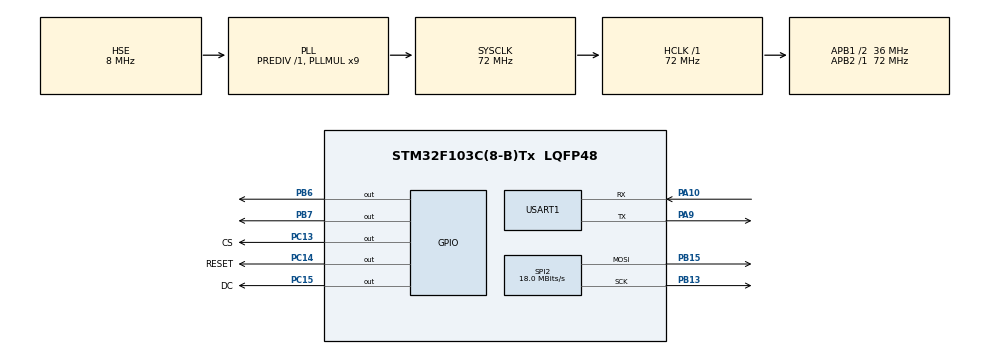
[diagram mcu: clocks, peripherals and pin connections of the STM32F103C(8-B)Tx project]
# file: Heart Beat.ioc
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Mcu.Family=STM32F1
Mcu.Name=STM32F103C(8-B)Tx
Mcu.Package=LQFP48
NVIC.PriorityGroup=NVIC_PRIORITYGROUP_4
NVIC.SPI2_IRQn=true\:2\:0\:true\:false\:true\:true\:true\:true
NVIC.USART1_IRQn=true\:1\:0\:true\:false\:true\:true\:true\:true
PA10.Mode=Asynchronous
PA10.Signal=USART1_RX
PA9.Mode=Asynchronous
PA9.Signal=USART1_TX
PB13.Mode=TX_Only_Simplex_Unidirect_Master
PB13.Signal=SPI2_SCK
PB15.Mode=TX_Only_Simplex_Unidirect_Master
PB15.Signal=SPI2_MOSI
PB6.GPIO_Speed=GPIO_SPEED_FREQ_HIGH
PB6.PinState=GPIO_PIN_SET
PB6.Signal=GPIO_Output
PB7.GPIO_Speed=GPIO_SPEED_FREQ_HIGH
PB7.PinState=GPIO_PIN_SET
PB7.Signal=GPIO_Output
PC13-TAMPER-RTC.GPIO_Label=CS
PC13-TAMPER-RTC.Signal=GPIO_Output
PC14-OSC32_IN.GPIO_Label=RESET
PC14-OSC32_IN.Signal=GPIO_Output
PC15-OSC32_OUT.GPIO_Label=DC
PC15-OSC32_OUT.Signal=GPIO_Output
PD0-OSC_IN.Mode=HSE-External-Oscillator
PD0-OSC_IN.Signal=RCC_OSC_IN
PD1-OSC_OUT.Mode=HSE-External-Oscillator
PD1-OSC_OUT.Signal=RCC_OSC_OUT
ProjectManager.HeapSize=0x200
ProjectManager.StackSize=0x400
ProjectManager.TargetToolchain=STM32CubeIDE
RCC.AHBFreq_Value=72000000
RCC.APB1CLKDivider=RCC_HCLK_DIV2
RCC.APB1Freq_Value=36000000
RCC.APB1TimFreq_Value=72000000
RCC.APB2Freq_Value=72000000
RCC.APB2TimFreq_Value=72000000
RCC.HCLKFreq_Value=72000000
RCC.PLLMUL=RCC_PLL_MUL9
RCC.PLLSourceVirtual=RCC_PLLSOURCE_HSE
RCC.SYSCLKFreq_VALUE=72000000
RCC.SYSCLKSource=RCC_SYSCLKSOURCE_PLLCLK
RCC.USBFreq_Value=72000000
SPI2.CalculateBaudRate=18.0 MBits/s
SPI2.Direction=SPI_DIRECTION_2LINES
SPI2.Mode=SPI_MODE_MASTER
SPI2.VirtualType=VM_MASTER
USART1.VirtualMode=VM_ASYNC
VP_SYS_VS_ND.Mode=No_Debug
board=custom

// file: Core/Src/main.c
/**
  ******************************************************************************
  * @file           : main.c
  * @brief          : Main program body (Final Working Version)
  ******************************************************************************
  */
#include "main.h"

/* USER CODE BEGIN Includes */
#include <ST7735.h>
#include "user_main.h"

/* USER CODE END Includes */

SPI_HandleTypeDef hspi2;

UART_HandleTypeDef huart1;

void SystemClock_Config(void);
static void MX_GPIO_Init(void);
static void MX_SPI2_Init(void);
static void MX_USART1_UART_Init(void);

int main(void)
{

  /* MCU Configuration--------------------------------------------------------*/

  /* Reset of all peripherals, Initializes the Flash interface and the Systick. */
  HAL_Init();

  /* Configure the system clock */
  SystemClock_Config();

  /* Initialize all configured peripherals */
  MX_GPIO_Init();
  MX_SPI2_Init();
  MX_USART1_UART_Init();
  /* USER CODE BEGIN 2 */
  User_Setup();
  /* USER CODE END 2 */

  /* Infinite loop */
  while (1)
  {

    /* USER CODE BEGIN 3 */
    User_Loop();
  }
  /* USER CODE END 3 */
}

void SystemClock_Config(void)
{
  RCC_OscInitTypeDef RCC_OscInitStruct = {0};
  RCC_ClkInitTypeDef RCC_ClkInitStruct = {0};

  /** Initializes the RCC Oscillators according to the specified parameters
  */
  RCC_OscInitStruct.OscillatorType = RCC_OSCILLATORTYPE_HSE;
  RCC_OscInitStruct.HSEState = RCC_HSE_ON;
  RCC_OscInitStruct.HSEPredivValue = RCC_HSE_PREDIV_DIV1;
  RCC_OscInitStruct.HSIState = RCC_HSI_ON;
  RCC_OscInitStruct.PLL.PLLState = RCC_PLL_ON;
  RCC_OscInitStruct.PLL.PLLSource = RCC_PLLSOURCE_HSE;
  RCC_OscInitStruct.PLL.PLLMUL = RCC_PLL_MUL9;
  if (HAL_RCC_OscConfig(&RCC_OscInitStruct) != HAL_OK)
  {
    Error_Handler();
  }

  /** Initializes the CPU, AHB and APB buses clocks
  */
  RCC_ClkInitStruct.ClockType = RCC_CLOCKTYPE_HCLK|RCC_CLOCKTYPE_SYSCLK
                              |RCC_CLOCKTYPE_PCLK1|RCC_CLOCKTYPE_PCLK2;
  RCC_ClkInitStruct.SYSCLKSource = RCC_SYSCLKSOURCE_PLLCLK;
  RCC_ClkInitStruct.AHBCLKDivider = RCC_SYSCLK_DIV1;
  RCC_ClkInitStruct.APB1CLKDivider = RCC_HCLK_DIV2;
  RCC_ClkInitStruct.APB2CLKDivider = RCC_HCLK_DIV1;

  if (HAL_RCC_ClockConfig(&RCC_ClkInitStruct, FLASH_LATENCY_2) != HAL_OK)
  {
    Error_Handler();
  }
}

static void MX_SPI2_Init(void)
{

  /* SPI2 parameter configuration*/
  hspi2.Instance = SPI2;
  hspi2.Init.Mode = SPI_MODE_MASTER;
  hspi2.Init.Direction = SPI_DIRECTION_2LINES;
  hspi2.Init.DataSize = SPI_DATASIZE_8BIT;
  hspi2.Init.CLKPolarity = SPI_POLARITY_LOW;
  hspi2.Init.CLKPhase = SPI_PHASE_1EDGE;
  hspi2.Init.NSS = SPI_NSS_SOFT;
  hspi2.Init.BaudRatePrescaler = SPI_BAUDRATEPRESCALER_2;
  hspi2.Init.FirstBit = SPI_FIRSTBIT_MSB;
  hspi2.Init.TIMode = SPI_TIMODE_DISABLE;
  hspi2.Init.CRCCalculation = SPI_CRCCALCULATION_DISABLE;
  hspi2.Init.CRCPolynomial = 10;
  if (HAL_SPI_Init(&hspi2) != HAL_OK)
  {
    Error_Handler();
  }

}

static void MX_USART1_UART_Init(void)
{

  huart1.Instance = USART1;
  huart1.Init.BaudRate = 115200;
  huart1.Init.WordLength = UART_WORDLENGTH_8B;
  huart1.Init.StopBits = UART_STOPBITS_1;
  huart1.Init.Parity = UART_PARITY_NONE;
  huart1.Init.Mode = UART_MODE_TX_RX;
  huart1.Init.HwFlowCtl = UART_HWCONTROL_NONE;
  huart1.Init.OverSampling = UART_OVERSAMPLING_16;
  if (HAL_UART_Init(&huart1) != HAL_OK)
  {
    Error_Handler();
  }

}

static void MX_GPIO_Init(void)
{
  GPIO_InitTypeDef GPIO_InitStruct = {0};

  /* GPIO Ports Clock Enable */
  __HAL_RCC_GPIOC_CLK_ENABLE();
  __HAL_RCC_GPIOD_CLK_ENABLE();
  __HAL_RCC_GPIOB_CLK_ENABLE();
  __HAL_RCC_GPIOA_CLK_ENABLE();

  /*Configure GPIO pin Output Level */
  HAL_GPIO_WritePin(GPIOC, CS_Pin|RESET_Pin|DC_Pin, GPIO_PIN_RESET);

  /*Configure GPIO pin Output Level */
  HAL_GPIO_WritePin(GPIOB, GPIO_PIN_6|GPIO_PIN_7, GPIO_PIN_SET); // PB6/PB7 (I2C/GPIO) set high

  /*Configure GPIO pins : CS_Pin RESET_Pin DC_Pin */
  GPIO_InitStruct.Pin = CS_Pin|RESET_Pin|DC_Pin;
  GPIO_InitStruct.Mode = GPIO_MODE_OUTPUT_PP;
  GPIO_InitStruct.Pull = GPIO_NOPULL;
  GPIO_InitStruct.Speed = GPIO_SPEED_FREQ_LOW;
  HAL_GPIO_Init(GPIOC, &GPIO_InitStruct);

  /*Configure GPIO pins : PB6 PB7 */
  GPIO_InitStruct.Pin = GPIO_PIN_6|GPIO_PIN_7;
  GPIO_InitStruct.Mode = GPIO_MODE_OUTPUT_PP;
  GPIO_InitStruct.Pull = GPIO_NOPULL;
  GPIO_InitStruct.Speed = GPIO_SPEED_FREQ_HIGH;
  HAL_GPIO_Init(GPIOB, &GPIO_InitStruct);

}

void Error_Handler(void)
{
  __disable_irq();
  while (1)
  {
  }
}
